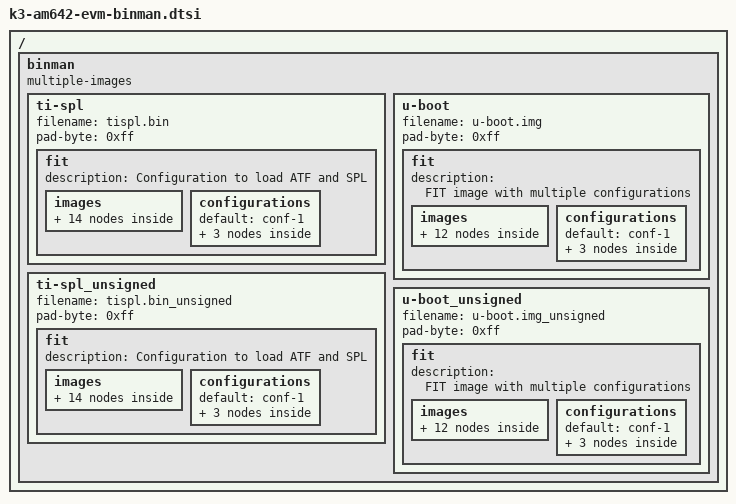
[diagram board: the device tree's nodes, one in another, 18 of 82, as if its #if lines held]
// SPDX-License-Identifier: GPL-2.0
/*
 * Copyright (C) 2021 Texas Instruments Incorporated - https://www.ti.com/
 */

/ {
	binman: binman {
		multiple-images;
	};
};

#ifdef CONFIG_TARGET_AM642_A53_EVM

#define SPL_NODTB "spl/u-boot-spl-nodtb.bin"
#define SPL_AM642_EVM_DTB "spl/dts/k3-am642-evm.dtb"
#define SPL_AM642_SK_DTB "spl/dts/k3-am642-sk.dtb"

#define UBOOT_NODTB "u-boot-nodtb.bin"
#define AM642_EVM_DTB "arch/arm/dts/k3-am642-evm.dtb"
#define AM642_SK_DTB "arch/arm/dts/k3-am642-sk.dtb"
#define AM642_NAND_DTB "arch/arm/dts/k3-am642-evm-nand.dtbo"

&binman {
	ti-spl {
		filename = "tispl.bin";
		pad-byte = <0xff>;

		fit {
			description = "Configuration to load ATF and SPL";
			#address-cells = <1>;

			images {

				atf {
					description = "ARM Trusted Firmware";
					type = "firmware";
					arch = "arm64";
					compression = "none";
					os = "arm-trusted-firmware";
					load = <CONFIG_K3_ATF_LOAD_ADDR>;
					entry = <CONFIG_K3_ATF_LOAD_ADDR>;
					atf-bl31 {
						filename = "bl31.bin";
					};
				};

				tee {
					description = "OPTEE";
					type = "tee";
					arch = "arm64";
					compression = "none";
					os = "tee";
					load = <0x9e800000>;
					entry = <0x9e800000>;
					tee-os {
						filename = "tee-pager_v2.bin";
					};
				};

				dm {
					description = "DM binary";
					type = "firmware";
					arch = "arm32";
					compression = "none";
					os = "DM";
					load = <0x89000000>;
					entry = <0x89000000>;
					blob-ext {
						filename = "/dev/null";
					};
				};

				spl {
					description = "SPL (64-bit)";
					type = "standalone";
					os = "U-Boot";
					arch = "arm64";
					compression = "none";
					load = <0x80080000>;
					entry = <0x80080000>;
					ti-secure {
						filename = SPL_NODTB;
					};
				};

				fdt-1 {
					description = "k3-am642-evm";
					type = "flat_dt";
					arch = "arm";
					compression = "none";
					ti-secure {
						filename = SPL_AM642_EVM_DTB;
					};
				};

				fdt-2 {
					description = "k3-am642-sk";
					type = "flat_dt";
					arch = "arm";
					compression = "none";
					ti-secure {
						filename = SPL_AM642_SK_DTB;
					};
				};

				fdt-3 {
					description = "k3-am642-evm-nand overlay";
					type = "flat_dt";
					arch = "arm";
					compression = "none";
					ti-secure {
						filename = AM642_NAND_DTB;
					};
				};
			};

			configurations {
				default = "conf-1";

				conf-1 {
					description = "k3-am642-evm";
					firmware = "atf";
					loadables = "tee", "dm", "spl";
					fdt = "fdt-1";
				};

				conf-2 {
					description = "k3-am642-sk";
					firmware = "atf";
					loadables = "tee", "dm", "spl";
					fdt = "fdt-2";
				};

				conf-3 {
					description = "k3-am642-evm-nand";
					firmware = "atf";
					loadables = "tee", "dm", "spl";
					fdt = "fdt-1", "fdt-3";
				};
			};
		};
	};
};

&binman {
	u-boot {
		filename = "u-boot.img";
		pad-byte = <0xff>;

		fit {
			description = "FIT image with multiple configurations";

			images {
				uboot {
					description = "U-Boot for am64x board";
					type = "firmware";
					os = "u-boot";
					arch = "arm";
					compression = "none";
					load = <CONFIG_SYS_TEXT_BASE>;
					ti-secure {
						filename = UBOOT_NODTB;
					};
					hash {
						algo = "crc32";
					};
				};

				fdt-1 {
					description = "k3-am642-evm";
					type = "flat_dt";
					arch = "arm";
					compression = "none";
					ti-secure {
						filename = AM642_EVM_DTB;
					};
					hash {
						algo = "crc32";
					};
				};

				fdt-2 {
					description = "k3-am642-sk";
					type = "flat_dt";
					arch = "arm";
					compression = "none";
					ti-secure {
						filename = AM642_SK_DTB;
					};
					hash {
						algo = "crc32";
					};
				};

				fdt-3 {
					description = "k3-am642-evm-nand overlay";
					type = "flat_dt";
					arch = "arm";
					compression = "none";
					ti-secure {
						filename = AM642_NAND_DTB;
					};
					hash {
						algo = "crc32";
					};
				};
			};

			configurations {
				default = "conf-1";

				conf-1 {
					description = "k3-am642-evm";
					firmware = "uboot";
					loadables = "uboot";
					fdt = "fdt-1";
				};

				conf-2 {
					description = "k3-am642-sk";
					firmware = "uboot";
					loadables = "uboot";
					fdt = "fdt-2";
				};

				conf-3 {
					description = "k3-am642-evm-nand";
					firmware = "uboot";
					loadables = "uboot";
					fdt = "fdt-1", "fdt-3";
				};
			};
		};
	};
};

&binman {
	ti-spl_unsigned {
		filename = "tispl.bin_unsigned";
		pad-byte = <0xff>;

		fit {
			description = "Configuration to load ATF and SPL";
			#address-cells = <1>;

			images {

				atf {
					description = "ARM Trusted Firmware";
					type = "firmware";
					arch = "arm64";
					compression = "none";
					os = "arm-trusted-firmware";
					load = <CONFIG_K3_ATF_LOAD_ADDR>;
					entry = <CONFIG_K3_ATF_LOAD_ADDR>;
					atf-bl31 {
						filename = "bl31.bin";
					};
				};

				tee {
					description = "OPTEE";
					type = "tee";
					arch = "arm64";
					compression = "none";
					os = "tee";
					load = <0x9e800000>;
					entry = <0x9e800000>;
					tee-os {
						filename = "tee-pager_v2.bin";
					};
				};

				dm {
					description = "DM binary";
					type = "firmware";
					arch = "arm32";
					compression = "none";
					os = "DM";
					load = <0x89000000>;
					entry = <0x89000000>;
					blob-ext {
						filename = "/dev/null";
					};
				};

				spl {
					description = "SPL (64-bit)";
					type = "standalone";
					os = "U-Boot";
					arch = "arm64";
					compression = "none";
					load = <0x80080000>;
					entry = <0x80080000>;
					blob {
						filename = SPL_NODTB;
					};
				};

				fdt-1 {
					description = "k3-am642-evm";
					type = "flat_dt";
					arch = "arm";
					compression = "none";
					blob {
						filename = SPL_AM642_EVM_DTB;
					};
				};

				fdt-2 {
					description = "k3-am642-sk";
					type = "flat_dt";
					arch = "arm";
					compression = "none";
					blob {
						filename = SPL_AM642_SK_DTB;
					};
				};

				fdt-3 {
					description = "k3-am642-evm-nand overlay";
					type = "flat_dt";
					arch = "arm";
					compression = "none";
					blob {
						filename = AM642_NAND_DTB;
					};
				};
			};

			configurations {
				default = "conf-1";

				conf-1 {
					description = "k3-am642-evm";
					firmware = "atf";
					loadables = "tee", "dm", "spl";
					fdt = "fdt-1";
				};

				conf-2 {
					description = "k3-am642-sk";
					firmware = "atf";
					loadables = "tee", "dm", "spl";
					fdt = "fdt-2";
				};

				conf-3 {
					description = "k3-am642-evm-nand";
					firmware = "atf";
					loadables = "tee", "dm", "spl";
					fdt = "fdt-1", "fdt-3";
				};
			};
		};
	};
};

&binman {
	u-boot_unsigned {
		filename = "u-boot.img_unsigned";
		pad-byte = <0xff>;

		fit {
			description = "FIT image with multiple configurations";

			images {
				uboot {
					description = "U-Boot for am64x board";
					type = "firmware";
					os = "u-boot";
					arch = "arm";
					compression = "none";
					load = <CONFIG_SYS_TEXT_BASE>;
					blob {
						filename = UBOOT_NODTB;
					};
					hash {
						algo = "crc32";
					};
				};

				fdt-1 {
					description = "k3-am642-evm";
					type = "flat_dt";
					arch = "arm";
					compression = "none";
					blob {
						filename = AM642_EVM_DTB;
					};
					hash {
						algo = "crc32";
					};
				};

				fdt-2 {
					description = "k3-am642-sk";
					type = "flat_dt";
					arch = "arm";
					compression = "none";
					blob {
						filename = AM642_SK_DTB;
					};
					hash {
						algo = "crc32";
					};
				};

				fdt-3 {
					description = "k3-am642-evm-nand overlay";
					type = "flat_dt";
					arch = "arm";
					compression = "none";
					blob {
						filename = AM642_NAND_DTB;
					};
					hash {
						algo = "crc32";
					};
				};
			};

			configurations {
				default = "conf-1";

				conf-1 {
					description = "k3-am642-evm";
					firmware = "uboot";
					loadables = "uboot";
					fdt = "fdt-1";
				};

				conf-2 {
					description = "k3-am642-sk";
					firmware = "uboot";
					loadables = "uboot";
					fdt = "fdt-2";
				};

				conf-3 {
					description = "k3-am642-evm-nand";
					firmware = "uboot";
					loadables = "uboot";
					fdt = "fdt-1", "fdt-3";
				};
			};
		};
	};
};

#endif
